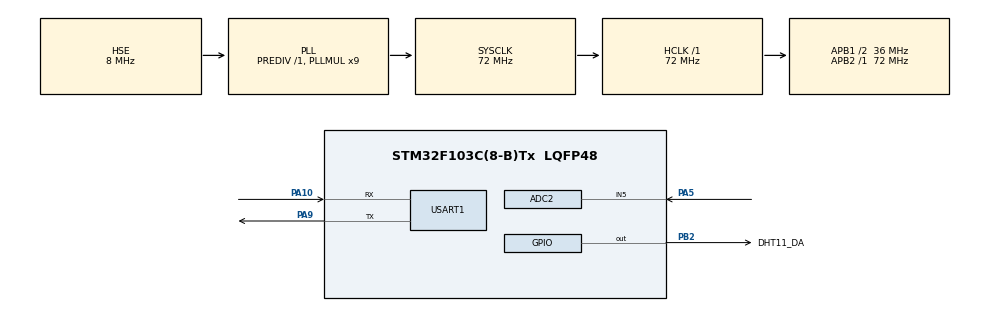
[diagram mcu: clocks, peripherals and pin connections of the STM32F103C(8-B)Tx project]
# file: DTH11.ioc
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ADC2.Channel-0\#ChannelRegularConversion=ADC_CHANNEL_5
ADC2.NbrOfConversionFlag=1
ADC2.Rank-0\#ChannelRegularConversion=1
ADC2.SamplingTime-0\#ChannelRegularConversion=ADC_SAMPLETIME_1CYCLE_5
Mcu.Family=STM32F1
Mcu.Name=STM32F103C(8-B)Tx
Mcu.Package=LQFP48
NVIC.PriorityGroup=NVIC_PRIORITYGROUP_4
NVIC.USART1_IRQn=true\:0\:0\:false\:false\:true\:true\:true\:true
PA10.Mode=Asynchronous
PA10.Signal=USART1_RX
PA13.Mode=JTAG_5_pins
PA13.Signal=SYS_JTMS-SWDIO
PA14.Mode=JTAG_5_pins
PA14.Signal=SYS_JTCK-SWCLK
PA15.Mode=JTAG_5_pins
PA15.Signal=SYS_JTDI
PA5.Signal=ADCx_IN5
PA9.Mode=Asynchronous
PA9.Signal=USART1_TX
PB2.GPIO_Label=DHT11_DA
PB2.GPIO_Speed=GPIO_SPEED_FREQ_HIGH
PB2.PinState=GPIO_PIN_SET
PB2.Signal=GPIO_Output
PB3.Mode=JTAG_5_pins
PB3.Signal=SYS_JTDO-TRACESWO
PB4.Mode=JTAG_5_pins
PB4.Signal=SYS_NJTRST
PC14-OSC32_IN.Mode=LSE-External-Oscillator
PC14-OSC32_IN.Signal=RCC_OSC32_IN
PC15-OSC32_OUT.Mode=LSE-External-Oscillator
PC15-OSC32_OUT.Signal=RCC_OSC32_OUT
PD0-OSC_IN.Mode=HSE-External-Oscillator
PD0-OSC_IN.Signal=RCC_OSC_IN
PD1-OSC_OUT.Mode=HSE-External-Oscillator
PD1-OSC_OUT.Signal=RCC_OSC_OUT
ProjectManager.HeapSize=0x200
ProjectManager.StackSize=0x400
ProjectManager.TargetToolchain=STM32CubeIDE
RCC.ADCPresc=RCC_ADCPCLK2_DIV8
RCC.AHBFreq_Value=72000000
RCC.APB1CLKDivider=RCC_HCLK_DIV2
RCC.APB1Freq_Value=36000000
RCC.APB1TimFreq_Value=72000000
RCC.APB2Freq_Value=72000000
RCC.APB2TimFreq_Value=72000000
RCC.HCLKFreq_Value=72000000
RCC.PLLMUL=RCC_PLL_MUL9
RCC.PLLSourceVirtual=RCC_PLLSOURCE_HSE
RCC.SYSCLKFreq_VALUE=72000000
RCC.SYSCLKSource=RCC_SYSCLKSOURCE_PLLCLK
RCC.USBFreq_Value=72000000
SH.ADCx_IN5.0=ADC2_IN5,IN5
USART1.VirtualMode=VM_ASYNC
VP_RTC_VS_RTC_Activate.Mode=RTC_Enabled
board=custom

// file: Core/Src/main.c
/* USER CODE BEGIN Header */
/**
  ******************************************************************************
  * @file           : main.c
  * @brief          : Main program body
  ******************************************************************************
  * @attention
  *
  * Copyright (c) 2025 STMicroelectronics.
  * All rights reserved.
  *
  * This software is licensed under terms that can be found in the LICENSE file
  * in the root directory of this software component.
  * If no LICENSE file comes with this software, it is provided AS-IS.
  *
  ******************************************************************************
  */
/* USER CODE END Header */
#include "main.h"
#include "adc.h"
#include "rtc.h"
#include "usart.h"
#include "gpio.h"

// #include "../../inode/led/led.h"
#include "../Inc/retarget.h"
#include "../../inode/usart/usart.h"
#include "../../inode/dht11/dht11.h"
#include "../../inode/adc/adc.h"
// #include "../../inode/wifi/wifi.h"

void SystemClock_Config(void);

int main(void)
{
  /* USER CODE BEGIN 1 */
  uint8_t DHT11_BUF[2]={0};
  uint16_t a;
  /* USER CODE END 1 */

  /* MCU Configuration--------------------------------------------------------*/

  /* Reset of all peripherals, Initializes the Flash interface and the Systick. */
  HAL_Init();

  /* Configure the system clock */
  SystemClock_Config();

  /* Initialize all configured peripherals */
  MX_GPIO_Init();
  MX_ADC2_Init();
  MX_RTC_Init();
  MX_USART1_UART_Init();

  RetargetInit(&huart1);
  HAL_UART_Receive_IT(&huart1,(uint8_t *)&USART1_NewData,1);
  HAL_ADCEx_Calibration_Start(&hadc2);
  HAL_Delay(500);
  DHT11_Init();
  HAL_Delay(1500);

  /* Infinite loop */
  while (1)
  {
    DHT11_ReadData(DHT11_BUF);

    char str[20];
    sprintf(str, "%d%%, %dC\r\n", DHT11_BUF[0], DHT11_BUF[1]);
    HAL_UART_Transmit_IT(&huart1, (uint8_t *)str, strlen(str));

    HAL_Delay(1000);
  }
}

void SystemClock_Config(void)
{
  RCC_OscInitTypeDef RCC_OscInitStruct = {0};
  RCC_ClkInitTypeDef RCC_ClkInitStruct = {0};
  RCC_PeriphCLKInitTypeDef PeriphClkInit = {0};

  /** Initializes the RCC Oscillators according to the specified parameters
  * in the RCC_OscInitTypeDef structure.
  */
  // RCC_OscInitStruct.OscillatorType = RCC_OSCILLATORTYPE_LSI|RCC_OSCILLATORTYPE_HSE;
  RCC_OscInitStruct.OscillatorType = RCC_OSCILLATORTYPE_HSE|RCC_OSCILLATORTYPE_LSE;
  RCC_OscInitStruct.HSEState = RCC_HSE_ON;
  RCC_OscInitStruct.HSEPredivValue = RCC_HSE_PREDIV_DIV1;
  RCC_OscInitStruct.HSIState = RCC_HSI_ON;
  // RCC_OscInitStruct.LSIState = RCC_LSI_ON;
  RCC_OscInitStruct.LSEState = RCC_LSE_ON;
  RCC_OscInitStruct.PLL.PLLState = RCC_PLL_ON;
  RCC_OscInitStruct.PLL.PLLSource = RCC_PLLSOURCE_HSE;
  RCC_OscInitStruct.PLL.PLLMUL = RCC_PLL_MUL9;
  if (HAL_RCC_OscConfig(&RCC_OscInitStruct) != HAL_OK)
  {
    Error_Handler();
  }

  /** Initializes the CPU, AHB and APB buses clocks
  */
  RCC_ClkInitStruct.ClockType = RCC_CLOCKTYPE_HCLK|RCC_CLOCKTYPE_SYSCLK
                              |RCC_CLOCKTYPE_PCLK1|RCC_CLOCKTYPE_PCLK2;
  RCC_ClkInitStruct.SYSCLKSource = RCC_SYSCLKSOURCE_PLLCLK;
  RCC_ClkInitStruct.AHBCLKDivider = RCC_SYSCLK_DIV1;
  RCC_ClkInitStruct.APB1CLKDivider = RCC_HCLK_DIV2;
  RCC_ClkInitStruct.APB2CLKDivider = RCC_HCLK_DIV1;

  if (HAL_RCC_ClockConfig(&RCC_ClkInitStruct, FLASH_LATENCY_2) != HAL_OK)
  {
    Error_Handler();
  }
  PeriphClkInit.PeriphClockSelection = RCC_PERIPHCLK_RTC|RCC_PERIPHCLK_ADC;
  // PeriphClkInit.RTCClockSelection = RCC_RTCCLKSOURCE_LSI;
  PeriphClkInit.RTCClockSelection = RCC_RTCCLKSOURCE_LSE;
  PeriphClkInit.AdcClockSelection = RCC_ADCPCLK2_DIV8;
  if (HAL_RCCEx_PeriphCLKConfig(&PeriphClkInit) != HAL_OK)
  {
    Error_Handler();
  }
}

void Error_Handler(void)
{
  __disable_irq();
  while (1)
  {
  }
}
